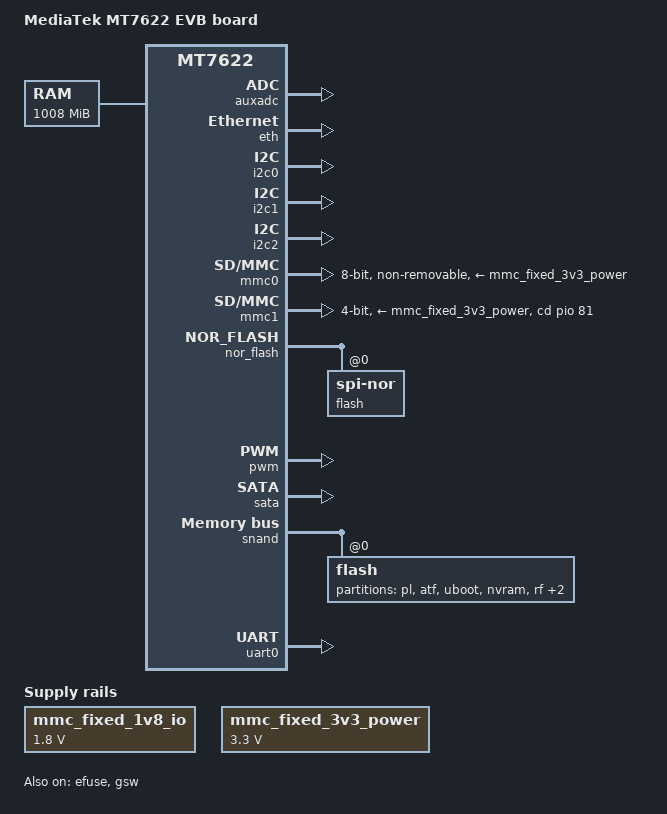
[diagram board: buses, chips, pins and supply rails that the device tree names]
/*
 * Copyright (c) 2016 MediaTek Inc.
 * Author: Ming Huang <ming.huang@mediatek.com>
 *
 * This program is free software; you can redistribute it and/or modify
 * it under the terms of the GNU General Public License version 2 as
 * published by the Free Software Foundation.
 *
 * This program is distributed in the hope that it will be useful,
 * but WITHOUT ANY WARRANTY; without even the implied warranty of
 * MERCHANTABILITY or FITNESS FOR A PARTICULAR PURPOSE.  See the
 * GNU General Public License for more details.
 */

/dts-v1/;
#include "mt7622.dtsi"

/ {
	model = "MediaTek MT7622 EVB board";
	compatible = "mediatek,mt7622-evb", "mediatek,mt7622";

	chosen {
		bootargs = "console=ttyS0,115200n1 root=/dev/ram \
			initrd=0x44000000,0x615E36 loglevel=8 androidboot.hardware=mt7622";
	};

	mmc_fixed_1v8_io: fixedregulator@0 {
		compatible = "regulator-fixed";
		regulator-name = "mmc_io";
		regulator-min-microvolt = <1800000>;
		regulator-max-microvolt = <1800000>;
		regulator-always-on;
	};

	mmc_fixed_3v3_power: fixedregulator@1 {
		compatible = "regulator-fixed";
		regulator-name = "mmc_power";
		regulator-min-microvolt = <3300000>;
		regulator-max-microvolt = <3300000>;
		regulator-always-on;
	};

	memory {
		reg = <0 0x40000000 0 0x3F000000>;
	};
};

&auxadc {
	status = "okay";
};

&efuse {
	status = "okay";
};

&eth {
	mac-address = [00 00 00 00 00 00];
	status = "okay";
	pinctrl-names = "default";
	pinctrl-0 = <&ephy_default>;
};

&gsw {
	status = "okay";
};

&i2c0 {
	status = "okay";
};

&i2c1 {
	status = "okay";
};

&i2c2 {
	status = "okay";
};

&mmc0 {
	pinctrl-names = "default", "state_uhs";
	pinctrl-0 = <&mmc0_pins_default>;
	pinctrl-1 = <&mmc0_pins_uhs>;
	status = "okay";
	bus-width = <8>;
	max-frequency = <50000000>;
	cap-mmc-highspeed;
	mmc-hs200-1_8v;
	vmmc-supply = <&mmc_fixed_3v3_power>;
	vqmmc-supply = <&mmc_fixed_1v8_io>;
	non-removable;
};

&mmc1 {
	pinctrl-names = "default", "state_uhs";
	pinctrl-0 = <&mmc1_pins_default>;
	pinctrl-1 = <&mmc1_pins_uhs>;
	status = "okay";
	bus-width = <4>;
	max-frequency = <50000000>;
	cap-sd-highspeed;
	cd-gpios = <&pio 81 0>;
	vmmc-supply = <&mmc_fixed_3v3_power>;
	vqmmc-supply = <&mmc_fixed_3v3_power>;
};

&nor_flash {
	status = "okay";
	flash@0 {
		compatible = "jedec,spi-nor";
	};
};

&pio {
	pinctrl-names = "default";
	pinctrl-0 = <&state_default>;
	state_default:pinconf_default {
	};

	mmc0_pins_default: mmc0default {
		pins_cmd_dat {
			pinmux = <MT7622_PIN_47_NDL0__FUNC_EMMC_DATA0>,
			       <MT7622_PIN_48_NDL1__FUNC_EMMC_DATA1>,
			       <MT7622_PIN_49_NDL2__FUNC_EMMC_DATA2>,
			       <MT7622_PIN_50_NDL3__FUNC_EMMC_DATA3>,
			       <MT7622_PIN_40_NDL4__FUNC_EMMC_DATA4>,
			       <MT7622_PIN_41_NDL5__FUNC_EMMC_DATA5>,
			       <MT7622_PIN_42_NDL6__FUNC_EMMC_DATA6>,
			       <MT7622_PIN_43_NDL7__FUNC_EMMC_DATA7>,
			       <MT7622_PIN_44_NRB__FUNC_EMMC_CMD>;
			input-enable;
			bias-pull-up;
		};

		pins_clk {
			pinmux = <MT7622_PIN_45_NCLE__FUNC_EMMC_CK>;
			bias-pull-down;
		};
	};

	mmc0_pins_uhs: mmc0@0{
		pins_cmd_dat {
			pinmux = <MT7622_PIN_47_NDL0__FUNC_EMMC_DATA0>,
			       <MT7622_PIN_48_NDL1__FUNC_EMMC_DATA1>,
			       <MT7622_PIN_49_NDL2__FUNC_EMMC_DATA2>,
			       <MT7622_PIN_50_NDL3__FUNC_EMMC_DATA3>,
			       <MT7622_PIN_40_NDL4__FUNC_EMMC_DATA4>,
			       <MT7622_PIN_41_NDL5__FUNC_EMMC_DATA5>,
			       <MT7622_PIN_42_NDL6__FUNC_EMMC_DATA6>,
			       <MT7622_PIN_43_NDL7__FUNC_EMMC_DATA7>,
			       <MT7622_PIN_44_NRB__FUNC_EMMC_CMD>;
			input-enable;
			drive-strength = <MTK_DRIVE_4mA>;
			bias-pull-up = <MTK_PUPD_SET_R1R0_01>;
		};

		pins_clk {
			pinmux = <MT7622_PIN_45_NCLE__FUNC_EMMC_CK>;
			drive-strength = <MTK_DRIVE_4mA>;
			bias-pull-down = <MTK_PUPD_SET_R1R0_10>;
		};
	};

	mmc1_pins_default: mmc1default {
		pins_cmd_dat {
			pinmux = <MT7622_PIN_19_I2S2_OUT__FUNC_SD_D0>,
			       <MT7622_PIN_18_I2S4_IN__FUNC_SD_D1>,
			       <MT7622_PIN_17_I2S3_IN__FUNC_SD_D2>,
			       <MT7622_PIN_16_I2S2_IN__FUNC_SD_D3>,
			       <MT7622_PIN_21_I2S4_OUT__FUNC_SD_CMD>;
			input-enable;
			drive-strength = <MTK_DRIVE_4mA>;
			bias-pull-up = <MTK_PUPD_SET_R1R0_01>;
		};

		pins_clk {
			pinmux = <MT7622_PIN_20_I2S3_OUT__FUNC_SD_CLK>;
			drive-strength = <MTK_DRIVE_4mA>;
			bias-pull-down = <MTK_PUPD_SET_R1R0_10>;
		};

		pins_insert {
			pinmux = <MT7622_PIN_81_TXD3__FUNC_GPIO81>;
			bias-pull-up;
		};
	};

	mmc1_pins_uhs: mmc1@0 {
		pins_cmd_dat {
			pinmux = <MT7622_PIN_19_I2S2_OUT__FUNC_SD_D0>,
			       <MT7622_PIN_18_I2S4_IN__FUNC_SD_D1>,
			       <MT7622_PIN_17_I2S3_IN__FUNC_SD_D2>,
			       <MT7622_PIN_16_I2S2_IN__FUNC_SD_D3>,
			       <MT7622_PIN_21_I2S4_OUT__FUNC_SD_CMD>;
			input-enable;
			drive-strength = <MTK_DRIVE_8mA>;
			bias-pull-up = <MTK_PUPD_SET_R1R0_01>;
		};

		pins_clk {
			pinmux = <MT7622_PIN_20_I2S3_OUT__FUNC_SD_CLK>;
			drive-strength = <MTK_DRIVE_8mA>;
			bias-pull-down = <MTK_PUPD_SET_R1R0_10>;
		};
	};

	snand_pins_default: snand@0 {
		pins_cmd_dat {
			pinmux = <MT7622_PIN_8_SPI_WP__FUNC_SNFI_WP>,
				 <MT7622_PIN_9_SPI_HOLD__FUNC_SNFI_HOLD>,
				 <MT7622_PIN_11_SPI_MOSI__FUNC_SNFI_MOSI>,
				 <MT7622_PIN_12_SPI_MISO__FUNC_SNFI_MISO>,
				 <MT7622_PIN_13_SPI_CS__FUNC_SNFI_CS>;
			input-enable;
			drive-strength = <MTK_DRIVE_8mA>;
			bias-pull-up = <MTK_PUPD_SET_R1R0_01>;
		};
		pins_clk {
			pinmux = <MT7622_PIN_10_SPI_CLK__FUNC_SNFI_CLK>;
			drive-strength = <MTK_DRIVE_8mA>;
			bias-pull-down = <MTK_PUPD_SET_R1R0_10>;
		};
	};
};

&pwm {
	status = "okay";
};

&sata {
	status = "okay";
};

&snand {
	pinctrl-0 = <&snand_pins_default>;
	status = "okay";
	flash@0 {
		partitions {
			compatible = "fixed-partitions";
			#address-cells = <1>;
			#size-cells = <1>;

			partition@0 {
				label = "pl";
				reg = <0x00000 0x0080000>;
				read-only;
			};

			partition@80000 {
				label = "atf";
				reg = <0x80000 0x0040000>;
			};

			partition@c0000 {
				label = "uboot";
				reg = <0xc0000 0x0080000>;
			};

			partition@140000 {
				label = "nvram";
				reg = <0x140000 0x0080000>;
			};

			partition@1c0000 {
				label = "rf";
				reg = <0x1c0000 0x0040000>;
			};

			partition@200000 {
				label = "kernel";
				reg = <0x200000 0x2000000>;
			};

			partition@2200000 {
				label = "user_data";
				reg = <0x2200000 0x4000000>;
			};
		};
	};
};

&uart0 {
	status = "okay";
};

&pcie0 {
	pinctrl-names = "default";
	pinctrl-0 = <&pcie_pinctl0>;
};

&pcie1 {
	pinctrl-names = "default";
	pinctrl-0 = <&pcie_pinctl1>;
};

&pio {
	ephy_default: ephy_default {
		pins_eth {
			pinmux = <MT7622_PIN_23_MDC__FUNC_MDC>,
				 <MT7622_PIN_24_MDIO__FUNC_MDIO>,
				 <MT7622_PIN_25_G2_TXD0__FUNC_G2_TXD0>,
				 <MT7622_PIN_26_G2_TXD1__FUNC_G2_TXD1>,
				 <MT7622_PIN_27_G2_TXD2__FUNC_G2_TXD2>,
				 <MT7622_PIN_28_G2_TXD3__FUNC_G2_TXD3>,
				 <MT7622_PIN_29_G2_TXEN__FUNC_G2_TXEN>,
				 <MT7622_PIN_30_G2_TXC__FUNC_G2_TXC>,
				 <MT7622_PIN_31_G2_RXD0__FUNC_G2_RXD0>,
				 <MT7622_PIN_32_G2_RXD1__FUNC_G2_RXD1>,
				 <MT7622_PIN_33_G2_RXD2__FUNC_G2_RXD2>,
				 <MT7622_PIN_34_G2_RXD3__FUNC_G2_RXD3>,
				 <MT7622_PIN_35_G2_RXDV__FUNC_G2_RXDV>,
				 <MT7622_PIN_36_G2_RXC__FUNC_G2_RXC>;
		};
	};

	pcie_pinctl0: pcie0 {
		pcie0 {
			pinmux = <MT7622_PIN_80_CTS3_N__FUNC_PCIE0_PAD_CLKREQ_N>,
				 <MT7622_PIN_79_RTS3_N__FUNC_PCIE0_PAD_WAKE_N>;
		};
	};

	pcie_pinctl1: pcie1 {
		pcie1 {
			pinmux = <MT7622_PIN_15_I2C_SCL__FUNC_PCIE0_PAD_CLKREQ_N>,
				 <MT7622_PIN_14_I2C_SDA__FUNC_PCIE0_PAD_WAKE_N>;
		};
	};
};
